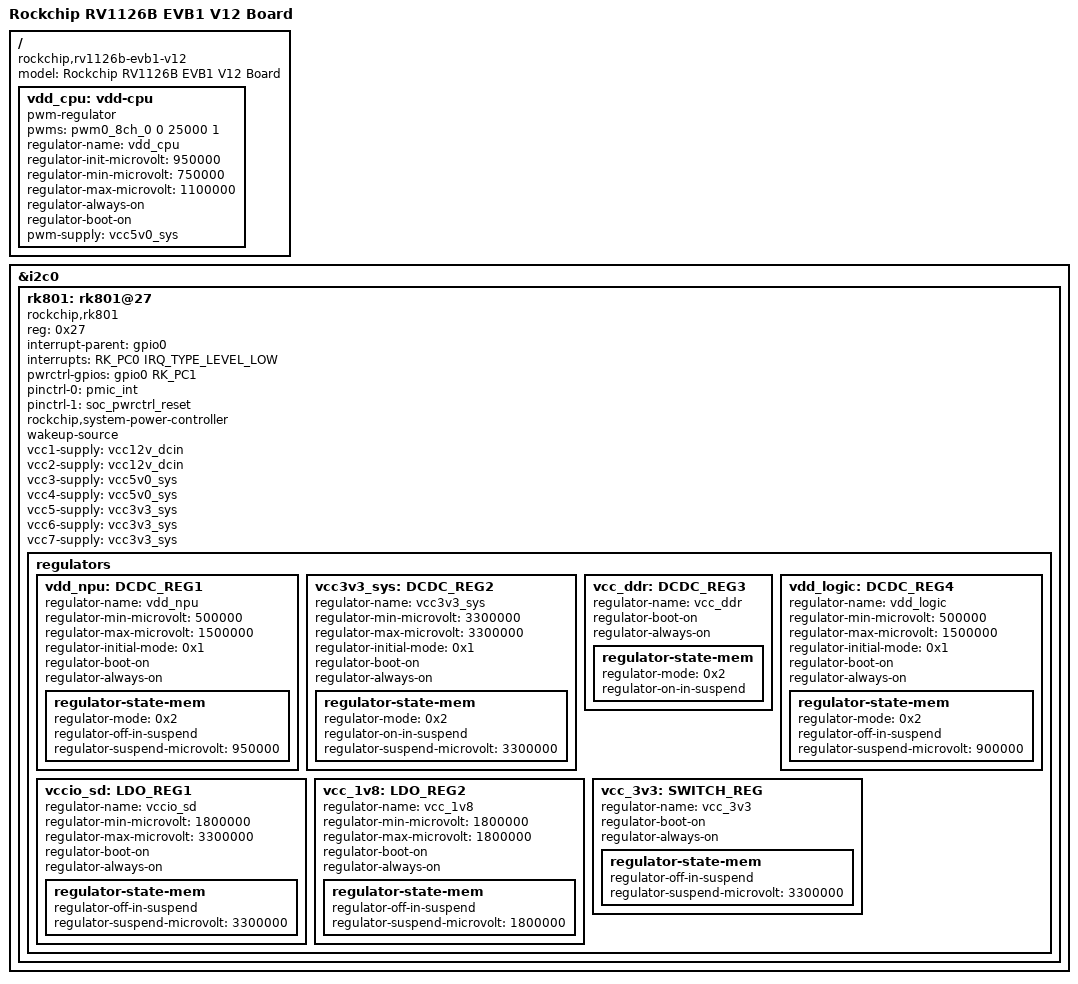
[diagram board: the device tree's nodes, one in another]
// SPDX-License-Identifier: (GPL-2.0+ OR MIT)
/*
 * Copyright (c) 2025 Rockchip Electronics Co., Ltd.
 *
 */

#include "rv1126b-evb1-v11.dtsi"

/delete-node/ &vccio_sd;
/delete-node/ &vdd_npu;
/delete-node/ &rk801;

/ {
	model = "Rockchip RV1126B EVB1 V12 Board";
	compatible = "rockchip,rv1126b-evb1-v12", "rockchip,rv1126b";

	vdd_cpu: vdd-cpu {
		compatible = "pwm-regulator";
		pwms = <&pwm0_8ch_0 0 25000 1>;
		regulator-name = "vdd_cpu";
		regulator-init-microvolt = <950000>;
		regulator-min-microvolt = <750000>;
		regulator-max-microvolt = <1100000>;
		regulator-always-on;
		regulator-boot-on;
		pwm-supply = <&vcc5v0_sys>;
	};
};

&i2c0 {
	status = "okay";

	rk801: rk801@27 {
		compatible = "rockchip,rk801";
		status = "okay";
		reg = <0x27>;
		interrupt-parent = <&gpio0>;
		interrupts = <RK_PC0 IRQ_TYPE_LEVEL_LOW>;
		pwrctrl-gpios = <&gpio0 RK_PC1 GPIO_ACTIVE_HIGH>;

		pinctrl-names = "default", "pmic-reset";
		pinctrl-0 = <&pmic_int>;
		pinctrl-1 = <&soc_pwrctrl_reset>;
		rockchip,system-power-controller;
		wakeup-source;

		vcc1-supply = <&vcc12v_dcin>;
		vcc2-supply = <&vcc12v_dcin>;
		vcc3-supply = <&vcc5v0_sys>;
		vcc4-supply = <&vcc5v0_sys>;
		vcc5-supply = <&vcc3v3_sys>;
		vcc6-supply = <&vcc3v3_sys>;
		vcc7-supply = <&vcc3v3_sys>;

		regulators {
			vdd_npu: DCDC_REG1 {
				regulator-name = "vdd_npu";
				regulator-min-microvolt = <500000>;
				regulator-max-microvolt = <1500000>;
				regulator-initial-mode = <0x1>;
				regulator-boot-on;
				regulator-always-on;
				regulator-state-mem {
					regulator-mode = <0x2>;
					regulator-off-in-suspend;
					regulator-suspend-microvolt = <950000>;
				};
			};

			vcc3v3_sys: DCDC_REG2 {
				regulator-name = "vcc3v3_sys";
				regulator-min-microvolt = <3300000>;
				regulator-max-microvolt = <3300000>;
				regulator-initial-mode = <0x1>;
				regulator-boot-on;
				regulator-always-on;
				regulator-state-mem {
					regulator-mode = <0x2>;
					regulator-on-in-suspend;
					regulator-suspend-microvolt = <3300000>;
				};
			};

			vcc_ddr: DCDC_REG3 {
				regulator-name = "vcc_ddr";
				regulator-boot-on;
				regulator-always-on;
				regulator-state-mem {
					regulator-mode = <0x2>;
					regulator-on-in-suspend;
				};
			};

			vdd_logic: DCDC_REG4 {
				regulator-name = "vdd_logic";
				regulator-min-microvolt = <500000>;
				regulator-max-microvolt = <1500000>;
				regulator-initial-mode = <0x1>;
				regulator-boot-on;
				regulator-always-on;
				regulator-state-mem {
					regulator-mode = <0x2>;
					regulator-off-in-suspend;
					regulator-suspend-microvolt = <900000>;
				};
			};

			vccio_sd: LDO_REG1 {
				regulator-name = "vccio_sd";
				regulator-min-microvolt = <1800000>;
				regulator-max-microvolt = <3300000>;
				regulator-boot-on;
				regulator-always-on;
				regulator-state-mem {
					regulator-off-in-suspend;
					regulator-suspend-microvolt = <3300000>;
				};
			};

			vcc_1v8: LDO_REG2 {
				regulator-name = "vcc_1v8";
				regulator-min-microvolt = <1800000>;
				regulator-max-microvolt = <1800000>;
				regulator-boot-on;
				regulator-always-on;
				regulator-state-mem {
					regulator-off-in-suspend;
					regulator-suspend-microvolt = <1800000>;
				};
			};

			vcc_3v3: SWITCH_REG {
				regulator-name = "vcc_3v3";
				regulator-boot-on;
				regulator-always-on;
				regulator-state-mem {
					regulator-off-in-suspend;
					regulator-suspend-microvolt = <3300000>;
				};
			};
		};
	};
};
